# AC7802x register map
Vendor: AutoChips; Series: AC78; File version: 1.0
CPU: CM0PLUS r0p1, little endian, no MPU, no FPU, VTOR, 2 interrupt priority bits
Registers are 32-bit, read-write, reset 0x0 unless marked. A register's access mark holds for its fields unless they carry their own. Offsets are from the block's base; [hi:lo] are bit positions; {n}, {i} and the like mark numbered series.

## PMUX — PinMux Function
Base 0x20080140
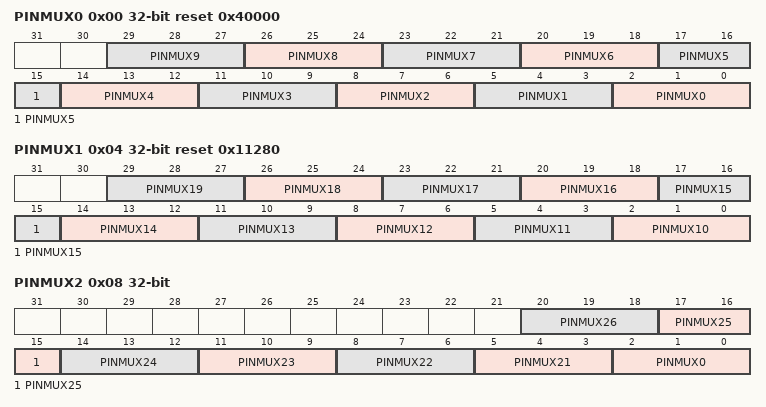
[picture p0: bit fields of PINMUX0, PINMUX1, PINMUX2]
0x00 PINMUX0 reset 0x40000 — PinMux Function Register 0
  [3n+2:3n] PINMUX{n} (n=0..9) — GPIO_PA{n} pinmux
    {v}=PA{n}_mux{v} (Function {v}) (v=0..3)
0x04 PINMUX1 reset 0x11280 — PinMux Function Register 1
  [3n-28:3n-30] PINMUX{n} (n=16..19) — GPIO_PB{n-16} pinmux
    {v}=PB{n-16}_mux{v} (Function {v}) (v=0..3)
  [3n-28:3n-30] PINMUX{n} (n=10..15) — GPIO_PA{n} pinmux
    {v}=PA{n}_mux{v} (Function {v}) (v=0..3)
0x08 PINMUX2 — PinMux Function Register 2
  [3n-58:3n-60] PINMUX{n} (n=21..26) — GPIO_PB{n-16} pinmux
    {v}=PB{n-16}_mux{v} (Function {v}) (v=0..3)
  [2:0] PINMUX0 — GPIO_PB4 pinmux
    {v}=PB4_mux{v} (Function {v}) (v=0..3)

## EXTI — External Interrupt
Base 0x20080160
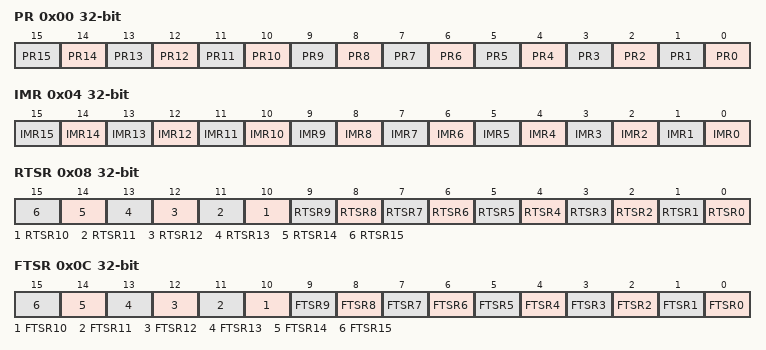
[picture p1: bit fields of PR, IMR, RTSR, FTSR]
0x00 PR — EXTI Pending Register
  [n] PR{n} (n=0..15) — GPIOx_PIN{n} exti flag
0x04 IMR — EXTI Mask Register
  [n] IMR{n} (n=0..15) — GPIOx_PIN{n} exti mask flag
0x08 RTSR — EXTI Rising edge Register
  [n] RTSR{n} (n=0..15) — GPIOx_PIN{n} exti rising edge enable flag
0x0C FTSR — EXTI Falling edge Register
  [n] FTSR{n} (n=0..15) — GPIOx_PIN{n} exti falling edge enable flag
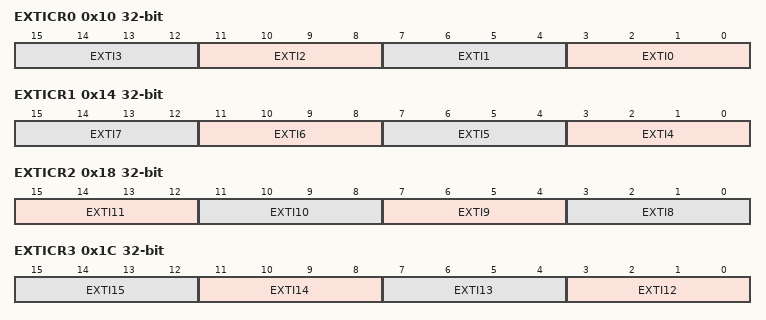
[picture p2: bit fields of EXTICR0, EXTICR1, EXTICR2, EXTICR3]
0x10 EXTICR0 — EXTI Control Register 0
  [4n+3:4n] EXTI{n} (n=0..3) — select PORTx for GPIOx_PIN{n} external interrupt
    0=PA[{n}] Pin; 1=PB[{n}] Pin
0x14 EXTICR1 — EXTI Control Register 1
  [4n-13:4n-16] EXTI{n} (n=4..7) — select PORTx for GPIOx_PIN{n} external interrupt
    0=PA[{n}] Pin; 1=PB[{n}] Pin
0x18 EXTICR2 — EXTI Control Register 2
  [15:12] EXTI11 — select PORTx for GPIOx_PIN11 external interrupt
    0=PA[11] Pin
  [11:8] EXTI10 — select PORTx for GPIOx_PIN10 external interrupt
    0=PA[10] Pin; 1=PB[10] Pin
  [7:4] EXTI9 — select PORTx for GPIOx_PIN9 external interrupt
    0=PA[9] Pin; 1=PB[9] Pin
  [3:0] EXTI8 — select PORTx for GPIOx_PIN8 external interrupt
    0=PA[8] Pin; 1=PB[8] Pin
0x1C EXTICR3 — EXTI Control Register 3
  [4n-45:4n-48] EXTI{n} (n=12..15) — select PORTx for GPIOx_PIN{n} external interrupt
    0=PA[{n}] Pin

## UART0 — Universal Asynchronous Receiver/Transmitter
Base 0x40018000
Same registers: UART1 0x4001A000
0x00 RBR reset not defined — RX/TX Data Register
  [8:0] RBR_THR
0x04 DIV_L reset 0x1 (reset mask 0x0) — Divisor low 8 bits register
  [7:0] DIV_L — uart baud rate divisor low 8 bits
0x08 DIV_H reset not defined — Divisor high 8 bits register
  [7:0] DIV_H — uart baud rate divisor high 8 bits
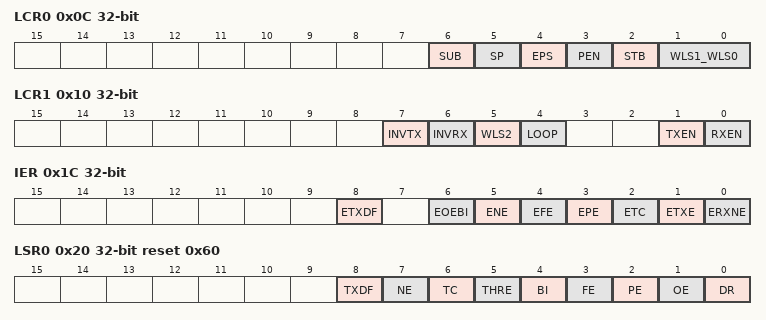
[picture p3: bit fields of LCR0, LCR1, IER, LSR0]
0x0C LCR0 reset not defined — uart control register 0
  [6] SUB — Sets up break
  [5] SP — stick parity
  [4] EPS — odd/eveen number select bit
  [3] PEN — uart parity enable/disable bit
  [2] STB — Number of STOP bits
  [1:0] WLS1_WLS0 — uart data mode select bits
    {v}={v+5}_BIT ({v+5} BITS) (v=0..3)
0x10 LCR1 reset not defined — uart control register 1
  [7] INVTX — uart tx output inverse enable/disable bit
  [6] INVRX — uart rx input inverse enable/disable bit
  [5] WLS2 — uart 9 bit data mode enable/disable bit
  [4] LOOP — uart loop back mode enable
  [1] TXEN — uart Transmitter enable
  [0] RXEN — uart receiver enable
0x14 FCR reset not defined — FIFO Control Register
  [0] FIFOE — RX and TX FIFO enable/disable bit
0x1C IER reset not defined — Interrupt Enable register
  [8] ETXDF — TX register or TX FIFO full interrupt enable bit
  [6] EOEBI — overflow error or break error interrupt enable bit
  [5] ENE — noise error interrupt enable bit
  [4] EFE — overflow or frame error interrupt enable bit
  [3] EPE — parity error interrupt enable bit
  [2] ETC — transmitting completed interrupt enable bit
  [1] ETXE — transmitting data empty interrupt enable bit
  [0] ERXNE — receiving data not empty interrupt enable bit
0x20 LSR0 reset 0x60 (reset mask 0x0) — Line Status Register 0
  [8] TXDF ro — TX register or TX FIFO full flag
  [7] NE — noise error flag
  [6] TC ro — Transmitting finished flag
  [5] THRE ro — TX holding register or TX FIFO empty flag
  [4] BI — break error flag
  [3] FE — frame error flag
  [2] PE — parity error flag
  [1] OE — overrun error flag
  [0] DR ro — Data ready flag
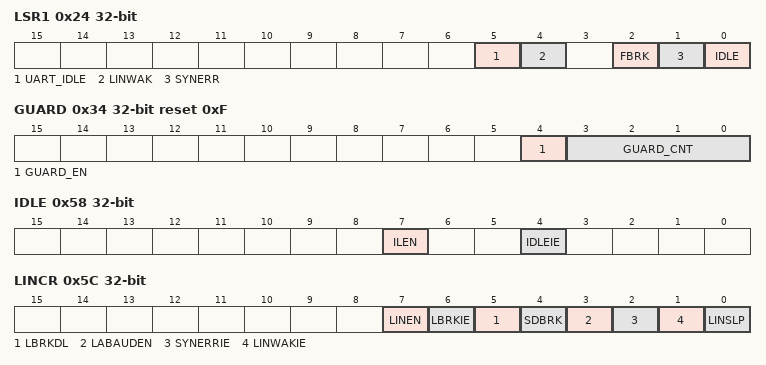
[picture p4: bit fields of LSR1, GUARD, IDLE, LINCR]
0x24 LSR1 reset not defined — Line Status Register 1
  [5] UART_IDLE ro
  [4] LINWAK ro — LIN wakeup flag
  [2] FBRK — LIN break occurred flag
  [1] SYNERR — LIN sync error flag
  [0] IDLE — IDLE flag
0x28 SMP_CNT reset not defined — uart sample counter register
  [1:0] SMP_CNT — uart sample counter
0x34 GUARD reset 0xF (reset mask 0x0) — uart guard time register
  [4] GUARD_EN — Guard interval time added enabling signal
  [3:0] GUARD_CNT — Guard interval count value
0x3C SLEEP_EN reset not defined — uart sleep enable register
  [0] SLEEP_EN — uart sleep function enable bit
0x44 DIV_FRAC reset not defined — Uart Fractional Divider Address
  [7:0] DIV_FRAC — uart fractional divider
0x58 IDLE reset not defined — Uart IDLE register
  [7] ILEN — Bus idle detect enable/disable
  [4] IDLEIE — IDLE interrupt enable bit
0x5C LINCR reset not defined — LIN Control register
  [7] LINEN — LIN mode enable/disable
  [6] LBRKIE — LIN break detection interrupt enable/disable
  [5] LBRKDL — LIN break detection threshold
  [4] SDBRK — LIN break transfer enable
  [3] LABAUDEN — LIN automatic baudrate detection enable/disable
  [2] SYNERRIE — LIN sync error interrupt enable/disable
  [1] LINWAKIE — LIN wakeup interrupt enable/disable
  [0] LINSLP — LIN sleep mode enable/disable
0x60 BRKLGH reset not defined — LIN Break Length Select Register
  [3:0] BRKLGH — LIN break length
